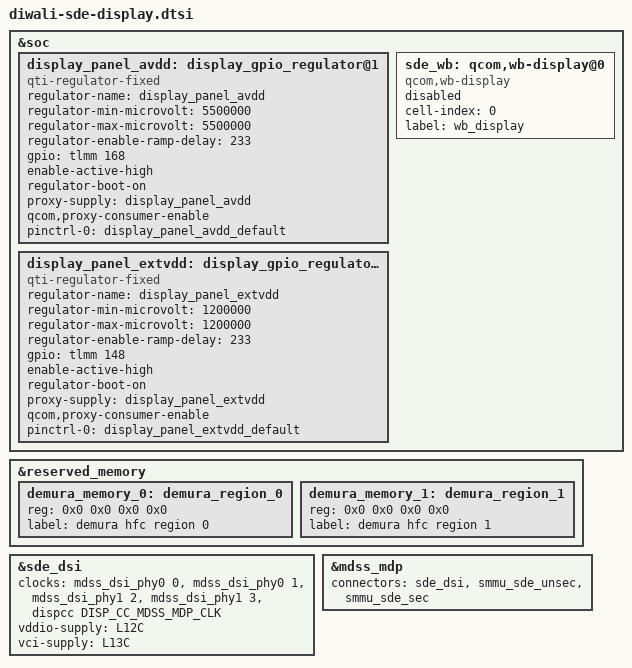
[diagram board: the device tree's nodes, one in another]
#include "diwali-sde-display-common.dtsi"
#include <dt-bindings/clock/qcom,dispcc-diwali.h>

&soc {
	display_panel_avdd: display_gpio_regulator@1 {
		compatible = "qti-regulator-fixed";
		regulator-name = "display_panel_avdd";
		regulator-min-microvolt = <5500000>;
		regulator-max-microvolt = <5500000>;
		regulator-enable-ramp-delay = <233>;
		gpio = <&tlmm 168 0>;
		enable-active-high;
		regulator-boot-on;
		proxy-supply = <&display_panel_avdd>;
		qcom,proxy-consumer-enable;
		pinctrl-names = "default";
		pinctrl-0 = <&display_panel_avdd_default>;
	};

	display_panel_extvdd: display_gpio_regulator@2 {
		compatible = "qti-regulator-fixed";
		regulator-name = "display_panel_extvdd";
		regulator-min-microvolt = <1200000>;
		regulator-max-microvolt = <1200000>;
		regulator-enable-ramp-delay = <233>;
		gpio = <&tlmm 148 0>;
		enable-active-high;
		regulator-boot-on;
		proxy-supply = <&display_panel_extvdd>;
		qcom,proxy-consumer-enable;
		pinctrl-names = "default";
		pinctrl-0 = <&display_panel_extvdd_default>;
	};

	sde_wb: qcom,wb-display@0 {
		compatible = "qcom,wb-display";
		status = "disabled";
		cell-index = <0>;
		label = "wb_display";
	};
};

&reserved_memory {
	/*
	 * Demura memory regions are to be commented out if
	 * feature not in use.
	 */
	demura_memory_0: demura_region_0 {
		reg = <0x0 0x0 0x0 0x0>;
		label = "demura hfc region 0";
	};
	demura_memory_1: demura_region_1 {
		reg = <0x0 0x0 0x0 0x0>;
		label = "demura hfc region 1";
	};
};

&sde_dsi {
	clocks = <&mdss_dsi_phy0 0>,
			<&mdss_dsi_phy0 1>,
			<&mdss_dsi_phy1 2>,
			<&mdss_dsi_phy1 3>,
			 /*
			  * Currently the dsi clock handles are under the dsi
			  * controller DT node. As soon as the controller probe
			  * finishes, the dispcc sync state can get called before
			  * the dsi_display probe potentially disturbing the clock
			  * votes for cont_splash use case. Hence we are no longer
			  * protected by the component model in this case against the
			  * disp cc sync state getting triggered after the dsi_ctrl
			  * probe. To protect against this incorrect sync state trigger
			  * add this dummy MDP clk vote handle to the dsi_display
			  * DT node. Since the dsi_display driver does not parse
			  * MDP clock nodes, no actual vote shall be added and this
			  * change is done just to satisfy sync state requirements.
			  */
			 <&dispcc DISP_CC_MDSS_MDP_CLK>;
	clock-names = "pll_byte_clk0", "pll_dsi_clk0",
			"pll_byte_clk1", "pll_dsi_clk1",
			"mdp_core_clk";

	vddio-supply = <&L12C>;
	vci-supply = <&L13C>;
};

&mdss_mdp {
	connectors = <&sde_dsi &smmu_sde_unsec &smmu_sde_sec>;
};


